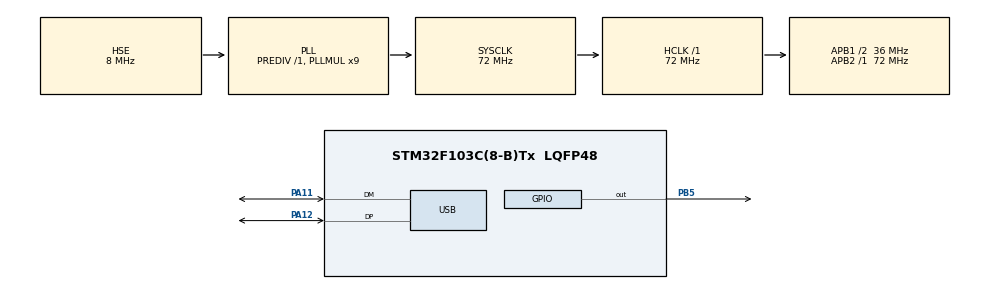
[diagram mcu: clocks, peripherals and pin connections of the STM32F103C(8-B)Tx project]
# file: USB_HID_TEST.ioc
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Mcu.Family=STM32F1
Mcu.Name=STM32F103C(8-B)Tx
Mcu.Package=LQFP48
NVIC.PriorityGroup=NVIC_PRIORITYGROUP_4
NVIC.USB_LP_CAN1_RX0_IRQn=true\:0\:0\:false\:false\:true\:false\:true\:true
PA11.Mode=Device
PA11.Signal=USB_DM
PA12.Mode=Device
PA12.Signal=USB_DP
PA13.Mode=Serial_Wire
PA13.Signal=SYS_JTMS-SWDIO
PA14.Mode=Serial_Wire
PA14.Signal=SYS_JTCK-SWCLK
PB5.Signal=GPIO_Output
PC14-OSC32_IN.Mode=LSE-External-Oscillator
PC14-OSC32_IN.Signal=RCC_OSC32_IN
PC15-OSC32_OUT.Mode=LSE-External-Oscillator
PC15-OSC32_OUT.Signal=RCC_OSC32_OUT
PD0-OSC_IN.Mode=HSE-External-Oscillator
PD0-OSC_IN.Signal=RCC_OSC_IN
PD1-OSC_OUT.Mode=HSE-External-Oscillator
PD1-OSC_OUT.Signal=RCC_OSC_OUT
ProjectManager.HeapSize=0x200
ProjectManager.StackSize=0x400
ProjectManager.TargetToolchain=STM32CubeIDE
RCC.AHBFreq_Value=72000000
RCC.APB1CLKDivider=RCC_HCLK_DIV2
RCC.APB1Freq_Value=36000000
RCC.APB1TimFreq_Value=72000000
RCC.APB2Freq_Value=72000000
RCC.APB2TimFreq_Value=72000000
RCC.HCLKFreq_Value=72000000
RCC.PLLMUL=RCC_PLL_MUL9
RCC.SYSCLKFreq_VALUE=72000000
RCC.SYSCLKSource=RCC_SYSCLKSOURCE_PLLCLK
RCC.USBFreq_Value=48000000
RCC.USBPrescaler=RCC_USBCLKSOURCE_PLL_DIV1_5
USB_DEVICE.CLASS_NAME_FS=CUSTOM_HID
USB_DEVICE.PID_CUSTOMHID_FS=22362 
USB_DEVICE.USBD_CUSTOMHID_OUTREPORT_BUF_SIZE=8
USB_DEVICE.USBD_CUSTOM_HID_REPORT_DESC_SIZE=3
USB_DEVICE.USBD_SELF_POWERED=1
USB_DEVICE.VirtualMode=CustomHid
USB_DEVICE.VirtualModeFS=Custom_Hid_FS
VP_USB_DEVICE_VS_USB_DEVICE_CUSTOM_HID_FS.Mode=CUSTOM_HID_FS
board=custom

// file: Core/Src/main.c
/* USER CODE BEGIN Header */
/**
  ******************************************************************************
  * @file           : main.c
  * @brief          : Main program body
  ******************************************************************************
  * @attention
  *
  * Copyright (c) 2023 STMicroelectronics.
  * All rights reserved.
  *
  * This software is licensed under terms that can be found in the LICENSE file
  * in the root directory of this software component.
  * If no LICENSE file comes with this software, it is provided AS-IS.
  *
  ******************************************************************************
  */
/* USER CODE END Header */
#include "main.h"
#include "usb_device.h"
#include "usbd_customhid.h"

void SystemClock_Config(void);
static void MX_GPIO_Init(void);

/* USER CODE BEGIN 0 */
char USB_RX_Buffer[65];
int USB_packet_enable = 0;
uint8_t USB_buffer_send_data[65];
extern USBD_HandleTypeDef hUsbDeviceFS;
/* USER CODE END 0 */

int main(void)
{

  /* MCU Configuration--------------------------------------------------------*/

  /* Reset of all peripherals, Initializes the Flash interface and the Systick. */
  HAL_Init();

  /* Configure the system clock */
  SystemClock_Config();

  /* Initialize all configured peripherals */
  MX_GPIO_Init();
  MX_USB_DEVICE_Init();
  /* USER CODE BEGIN 2 */
  USB_buffer_send_data[0] = 0x42;
  USB_buffer_send_data[1] = 0x33;
  USB_buffer_send_data[2] = 0x32;
  USB_buffer_send_data[3] = 0x33;
  USB_buffer_send_data[4] = 0x34;
  USB_buffer_send_data[5] = 0x35;
  USB_buffer_send_data[6] = 0x36;
  USB_buffer_send_data[7] = 0x20;

 /* typedef struct
  {
	  uint8_t a;
	  uint8_t b;
	  uint8_t c;
	  uint8_t d;
	  uint8_t e;
  }testData;*/

 // testData  USB_buffer_send_data = {1, 2, 3, 4, 5};

  /* USER CODE END 2 */

      /* USER CODE BEGIN 3 */
  /* Infinite loop */
  /* USER CODE BEGIN WHILE */
  while (1)
  {
    /* USER CODE END WHILE */

	  if(USB_packet_enable == 1)
	      {
	     	if(USB_RX_Buffer[0] == 2 && USB_RX_Buffer[1] == 1)
	     	{
	     		HAL_GPIO_WritePin(GPIOB, GPIO_PIN_5, GPIO_PIN_SET);
	     	}
	     	if(USB_RX_Buffer[0] == 2 && USB_RX_Buffer[1] == 0)
	     	{
	     	   HAL_GPIO_WritePin(GPIOB, GPIO_PIN_5, GPIO_PIN_RESET);
	       	}

	     	USB_packet_enable = 0;
	      }
	  if(USB_RX_Buffer[0] == 2 && USB_RX_Buffer[1] == 3)
	  {
	   	HAL_GPIO_TogglePin(GPIOB, GPIO_PIN_5);

	  }

	  USBD_CUSTOM_HID_SendReport(&hUsbDeviceFS, USB_buffer_send_data, 65);
	  HAL_Delay(100);
  }

 // USBD_CUSTOM_HID_SendReport(&hUsbDeviceFS, USB_buffer_send_data, 65);
  /* USER CODE END 3 */
}

void SystemClock_Config(void)
{
  RCC_OscInitTypeDef RCC_OscInitStruct = {0};
  RCC_ClkInitTypeDef RCC_ClkInitStruct = {0};
  RCC_PeriphCLKInitTypeDef PeriphClkInit = {0};

  /** Initializes the RCC Oscillators according to the specified parameters
  * in the RCC_OscInitTypeDef structure.
  */
  RCC_OscInitStruct.OscillatorType = RCC_OSCILLATORTYPE_HSE;
  RCC_OscInitStruct.HSEState = RCC_HSE_ON;
  RCC_OscInitStruct.HSEPredivValue = RCC_HSE_PREDIV_DIV1;
  RCC_OscInitStruct.HSIState = RCC_HSI_ON;
  RCC_OscInitStruct.PLL.PLLState = RCC_PLL_ON;
  RCC_OscInitStruct.PLL.PLLSource = RCC_PLLSOURCE_HSE;
  RCC_OscInitStruct.PLL.PLLMUL = RCC_PLL_MUL9;
  if (HAL_RCC_OscConfig(&RCC_OscInitStruct) != HAL_OK)
  {
    Error_Handler();
  }

  /** Initializes the CPU, AHB and APB buses clocks
  */
  RCC_ClkInitStruct.ClockType = RCC_CLOCKTYPE_HCLK|RCC_CLOCKTYPE_SYSCLK
                              |RCC_CLOCKTYPE_PCLK1|RCC_CLOCKTYPE_PCLK2;
  RCC_ClkInitStruct.SYSCLKSource = RCC_SYSCLKSOURCE_PLLCLK;
  RCC_ClkInitStruct.AHBCLKDivider = RCC_SYSCLK_DIV1;
  RCC_ClkInitStruct.APB1CLKDivider = RCC_HCLK_DIV2;
  RCC_ClkInitStruct.APB2CLKDivider = RCC_HCLK_DIV1;

  if (HAL_RCC_ClockConfig(&RCC_ClkInitStruct, FLASH_LATENCY_2) != HAL_OK)
  {
    Error_Handler();
  }
  PeriphClkInit.PeriphClockSelection = RCC_PERIPHCLK_USB;
  PeriphClkInit.UsbClockSelection = RCC_USBCLKSOURCE_PLL_DIV1_5;
  if (HAL_RCCEx_PeriphCLKConfig(&PeriphClkInit) != HAL_OK)
  {
    Error_Handler();
  }
}

static void MX_GPIO_Init(void)
{
  GPIO_InitTypeDef GPIO_InitStruct = {0};

  /* GPIO Ports Clock Enable */
  __HAL_RCC_GPIOC_CLK_ENABLE();
  __HAL_RCC_GPIOD_CLK_ENABLE();
  __HAL_RCC_GPIOA_CLK_ENABLE();
  __HAL_RCC_GPIOB_CLK_ENABLE();

  /*Configure GPIO pin Output Level */
  HAL_GPIO_WritePin(GPIOB, GPIO_PIN_5, GPIO_PIN_RESET);

  /*Configure GPIO pin : PB5 */
  GPIO_InitStruct.Pin = GPIO_PIN_5;
  GPIO_InitStruct.Mode = GPIO_MODE_OUTPUT_PP;
  GPIO_InitStruct.Pull = GPIO_NOPULL;
  GPIO_InitStruct.Speed = GPIO_SPEED_FREQ_LOW;
  HAL_GPIO_Init(GPIOB, &GPIO_InitStruct);

}

void Error_Handler(void)
{
  __disable_irq();
  while (1)
  {
  }
}
